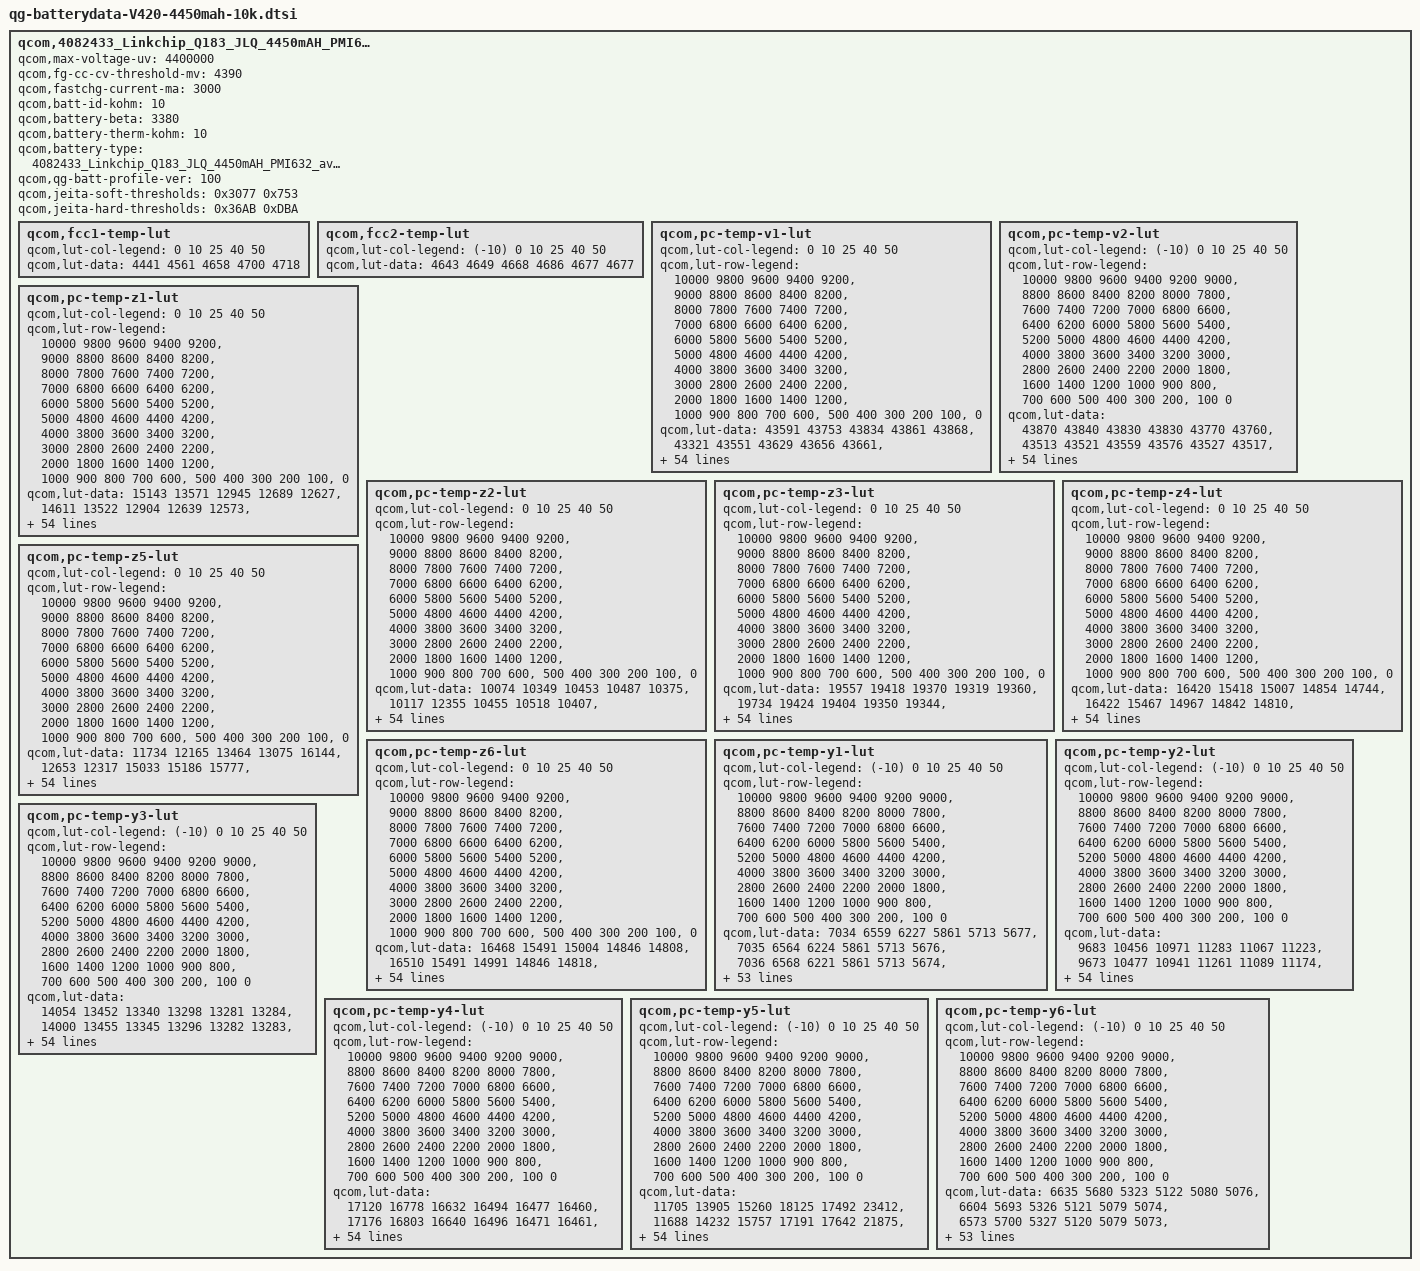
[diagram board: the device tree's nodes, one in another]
qcom,4082433_Linkchip_Q183_JLQ_4450mAH_PMI632 {
    /* 4082433_Linkchip_Q183_JLQ_4450mAH_PMI632_averaged_MasterSlave_Jul1th2019 */
    qcom,max-voltage-uv = <4400000>;
    qcom,fg-cc-cv-threshold-mv = <4390>;
    qcom,fastchg-current-ma = <3000>;
    qcom,batt-id-kohm = <10>;
    qcom,battery-beta = <3380>;
    qcom,battery-therm-kohm = <10>;
    qcom,battery-type = "4082433_Linkchip_Q183_JLQ_4450mAH_PMI632_averaged_MasterSlave_Jul1th2019";
    qcom,qg-batt-profile-ver = <100>;
    /* COOL = 5 DegC, WARM = 45 DegC */
    qcom,jeita-soft-thresholds = <0x3077 0x753>;
    /* COLD = 0 DegC, HOT = 50 DegC */
    qcom,jeita-hard-thresholds = <0x36AB 0xDBA>;
	qcom,fcc1-temp-lut {
		qcom,lut-col-legend = <0 10 25 40 50>;
		qcom,lut-data = <4441 4561 4658 4700 4718>;
	};

	qcom,fcc2-temp-lut {
		qcom,lut-col-legend = <(-10) 0 10 25 40 50>;
		qcom,lut-data = <4643 4649 4668 4686 4677 4677>;
	};

	qcom,pc-temp-v1-lut {
		qcom,lut-col-legend = <0 10 25 40 50>;
		qcom,lut-row-legend = <10000 9800 9600 9400 9200>,
			<9000 8800 8600 8400 8200>,
			<8000 7800 7600 7400 7200>,
			<7000 6800 6600 6400 6200>,
			<6000 5800 5600 5400 5200>,
			<5000 4800 4600 4400 4200>,
			<4000 3800 3600 3400 3200>,
			<3000 2800 2600 2400 2200>,
			<2000 1800 1600 1400 1200>,
			<1000 900 800 700 600>,
			<500 400 300 200 100>,
			<0>;
		qcom,lut-data = <43591 43753 43834 43861 43868>,
			<43321 43551 43629 43656 43661>,
			<43061 43282 43402 43441 43451>,
			<42814 43041 43171 43219 43235>,
			<42578 42801 42931 42986 43006>,
			<42350 42560 42691 42750 42773>,
			<42129 42324 42453 42516 42538>,
			<41914 42096 42218 42282 42301>,
			<41702 41875 41987 42050 42068>,
			<41489 41657 41760 41819 41837>,
			<41289 41441 41535 41591 41609>,
			<41119 41238 41313 41366 41384>,
			<40950 41065 41104 41146 41162>,
			<40722 40896 40920 40935 40950>,
			<40413 40669 40734 40729 40745>,
			<40152 40373 40509 40527 40544>,
			<39978 40131 40262 40327 40348>,
			<39836 39975 40068 40139 40160>,
			<39702 39843 39923 39970 39987>,
			<39581 39706 39776 39802 39816>,
			<39462 39572 39608 39612 39626>,
			<39339 39423 39425 39405 39417>,
			<39217 39253 39203 39201 39213>,
			<39100 39073 38939 38989 39008>,
			<38987 38877 38760 38813 38830>,
			<38879 38677 38661 38694 38704>,
			<38778 38552 38580 38595 38601>,
			<38682 38476 38496 38496 38497>,
			<38593 38417 38418 38401 38396>,
			<38509 38367 38346 38314 38304>,
			<38437 38325 38278 38237 38223>,
			<38378 38287 38218 38168 38150>,
			<38328 38253 38169 38108 38088>,
			<38284 38220 38123 38054 38032>,
			<38247 38191 38080 38001 37973>,
			<38208 38159 38039 37951 37909>,
			<38168 38121 37995 37899 37845>,
			<38125 38077 37950 37848 37786>,
			<38068 38019 37894 37788 37720>,
			<37995 37936 37810 37705 37634>,
			<37905 37830 37700 37599 37527>,
			<37783 37706 37580 37481 37406>,
			<37639 37559 37444 37344 37267>,
			<37482 37404 37290 37196 37117>,
			<37341 37262 37148 37058 36984>,
			<37232 37161 37063 36973 36914>,
			<37194 37132 37038 36949 36888>,
			<37172 37107 37022 36932 36870>,
			<37142 37084 37004 36912 36851>,
			<37094 37040 36952 36846 36771>,
			<36888 36826 36714 36577 36482>,
			<36458 36401 36283 36128 36028>,
			<35888 35837 35714 35548 35451>,
			<35127 35075 34941 34759 34660>,
			<33954 33914 33760 33544 33439>,
			<30000 30000 30000 30000 30000>;
	};

	qcom,pc-temp-v2-lut {
		qcom,lut-col-legend = <(-10) 0 10 25 40 50>;
		qcom,lut-row-legend = <10000 9800 9600 9400 9200 9000>,
			<8800 8600 8400 8200 8000 7800>,
			<7600 7400 7200 7000 6800 6600>,
			<6400 6200 6000 5800 5600 5400>,
			<5200 5000 4800 4600 4400 4200>,
			<4000 3800 3600 3400 3200 3000>,
			<2800 2600 2400 2200 2000 1800>,
			<1600 1400 1200 1000 900 800>,
			<700 600 500 400 300 200>,
			<100 0>;
		qcom,lut-data = <43870 43840 43830 43830 43770 43760>,
			<43513 43521 43559 43576 43527 43517>,
			<43175 43222 43297 43327 43287 43277>,
			<42857 42946 43044 43083 43048 43039>,
			<42557 42690 42800 42843 42813 42804>,
			<42275 42438 42557 42603 42577 42568>,
			<42013 42182 42315 42364 42340 42332>,
			<41762 41938 42077 42128 42104 42097>,
			<41500 41722 41846 41897 41871 41866>,
			<41248 41522 41620 41670 41641 41638>,
			<41075 41316 41395 41443 41414 41411>,
			<40973 41102 41171 41217 41191 41189>,
			<40834 40888 40961 41001 40972 40970>,
			<40455 40689 40786 40807 40763 40759>,
			<39977 40478 40609 40612 40557 40552>,
			<39700 40193 40370 40384 40356 40352>,
			<39511 39830 40076 40138 40160 40159>,
			<39336 39563 39828 39943 39976 39975>,
			<39168 39396 39629 39798 39809 39806>,
			<39007 39247 39440 39642 39632 39628>,
			<38844 39073 39241 39418 39415 39414>,
			<38686 38897 39046 39173 39184 39189>,
			<38545 38737 38874 38968 38980 38986>,
			<38416 38591 38718 38784 38791 38797>,
			<38306 38453 38580 38631 38636 38640>,
			<38216 38316 38459 38508 38512 38515>,
			<38138 38194 38352 38400 38405 38405>,
			<38070 38103 38251 38299 38304 38303>,
			<38010 38031 38158 38207 38212 38210>,
			<37951 37970 38072 38124 38129 38123>,
			<37895 37920 37993 38049 38053 38045>,
			<37841 37874 37921 37979 37982 37973>,
			<37788 37830 37856 37913 37919 37911>,
			<37735 37786 37798 37849 37856 37848>,
			<37679 37741 37753 37788 37780 37766>,
			<37620 37695 37716 37729 37693 37666>,
			<37556 37643 37674 37664 37607 37567>,
			<37491 37581 37626 37592 37519 37466>,
			<37423 37510 37568 37518 37434 37372>,
			<37356 37429 37494 37445 37358 37292>,
			<37287 37337 37403 37365 37281 37213>,
			<37221 37244 37297 37267 37184 37120>,
			<37148 37148 37178 37148 37068 37005>,
			<37070 37058 37049 37016 36935 36873>,
			<36979 36949 36944 36899 36823 36766>,
			<36865 36839 36872 36858 36797 36740>,
			<36800 36785 36839 36844 36783 36730>,
			<36728 36712 36810 36826 36765 36715>,
			<36622 36632 36762 36790 36739 36686>,
			<36468 36537 36665 36694 36629 36554>,
			<36241 36343 36425 36379 36291 36200>,
			<35884 35980 35947 35890 35797 35712>,
			<35365 35417 35318 35260 35168 35067>,
			<34582 34610 34475 34387 34300 34201>,
			<33313 33287 33171 33114 32972 32855>,
			<31074 30710 30689 30381 29206 29172>;
	};

	qcom,pc-temp-z1-lut {
		qcom,lut-col-legend = <0 10 25 40 50>;
		qcom,lut-row-legend = <10000 9800 9600 9400 9200>,
			<9000 8800 8600 8400 8200>,
			<8000 7800 7600 7400 7200>,
			<7000 6800 6600 6400 6200>,
			<6000 5800 5600 5400 5200>,
			<5000 4800 4600 4400 4200>,
			<4000 3800 3600 3400 3200>,
			<3000 2800 2600 2400 2200>,
			<2000 1800 1600 1400 1200>,
			<1000 900 800 700 600>,
			<500 400 300 200 100>,
			<0>;
		qcom,lut-data = <15143 13571 12945 12689 12627>,
			<14611 13522 12904 12639 12573>,
			<14256 13504 12872 12616 12556>,
			<14178 13482 12853 12604 12540>,
			<14154 13464 12842 12593 12533>,
			<14141 13447 12831 12584 12528>,
			<14131 13433 12819 12579 12525>,
			<14123 13422 12811 12575 12523>,
			<14114 13413 12805 12572 12521>,
			<14104 13405 12800 12569 12519>,
			<14093 13399 12797 12569 12518>,
			<14079 13392 12795 12569 12520>,
			<14062 13382 12793 12569 12524>,
			<14041 13368 12789 12569 12524>,
			<14012 13350 12784 12569 12523>,
			<13989 13326 12780 12569 12523>,
			<13974 13315 12775 12570 12526>,
			<13962 13320 12775 12571 12529>,
			<13957 13329 12782 12573 12529>,
			<13955 13335 12789 12575 12529>,
			<13952 13338 12792 12576 12529>,
			<13949 13344 12795 12577 12530>,
			<13947 13359 12798 12578 12532>,
			<13946 13371 12800 12579 12533>,
			<13946 13369 12803 12581 12535>,
			<13946 13366 12807 12585 12538>,
			<13945 13365 12810 12588 12541>,
			<13944 13374 12814 12592 12544>,
			<13944 13382 12818 12595 12549>,
			<13947 13384 12822 12599 12552>,
			<13952 13385 12827 12603 12555>,
			<13957 13389 12831 12608 12557>,
			<13963 13397 12835 12611 12560>,
			<13970 13406 12839 12615 12564>,
			<13977 13411 12844 12619 12568>,
			<13985 13415 12851 12622 12572>,
			<13993 13424 12857 12626 12576>,
			<14003 13440 12864 12630 12578>,
			<14014 13452 12871 12634 12580>,
			<14027 13460 12876 12640 12585>,
			<14041 13467 12881 12645 12591>,
			<14053 13478 12887 12650 12595>,
			<14066 13491 12894 12655 12598>,
			<14082 13505 12902 12659 12603>,
			<14099 13519 12911 12664 12608>,
			<14109 13521 12920 12670 12608>,
			<14106 13521 12921 12671 12611>,
			<14105 13525 12924 12673 12615>,
			<14110 13535 12929 12677 12620>,
			<14122 13548 12937 12685 12625>,
			<14140 13560 12948 12694 12634>,
			<14153 13570 12962 12706 12646>,
			<14170 13593 12980 12720 12660>,
			<14194 13630 13008 12741 12679>,
			<14194 13630 13008 12741 12679>,
			<14194 13630 13008 12741 12679>;
	};

	qcom,pc-temp-z2-lut {
		qcom,lut-col-legend = <0 10 25 40 50>;
		qcom,lut-row-legend = <10000 9800 9600 9400 9200>,
			<9000 8800 8600 8400 8200>,
			<8000 7800 7600 7400 7200>,
			<7000 6800 6600 6400 6200>,
			<6000 5800 5600 5400 5200>,
			<5000 4800 4600 4400 4200>,
			<4000 3800 3600 3400 3200>,
			<3000 2800 2600 2400 2200>,
			<2000 1800 1600 1400 1200>,
			<1000 900 800 700 600>,
			<500 400 300 200 100>,
			<0>;
		qcom,lut-data = <10074 10349 10453 10487 10375>,
			<10117 12355 10455 10518 10407>,
			<10156 10282 10500 10394 10324>,
			<10189 10265 10491 10548 10323>,
			<10219 10248 10476 10530 10404>,
			<10242 10229 10462 10504 10496>,
			<10262 10213 10453 10474 10489>,
			<10275 10202 10442 10442 10452>,
			<10274 10194 10423 10427 10425>,
			<10258 10184 10402 10418 10404>,
			<10240 10169 10393 10411 10394>,
			<10229 10161 10388 10405 10400>,
			<10217 10219 10387 10398 10407>,
			<10190 10309 10396 10364 10375>,
			<10133 10303 10408 10308 10279>,
			<10097 10207 10417 10304 10249>,
			<10092 10157 10424 10354 10272>,
			<10089 10177 10434 10383 10295>,
			<10087 10208 10445 10373 10304>,
			<10085 10226 10459 10361 10313>,
			<10083 10239 10483 10420 10383>,
			<10076 10254 10506 10575 10583>,
			<10068 10275 10506 10609 10651>,
			<10063 10290 10496 10518 10531>,
			<10060 10290 10482 10447 10428>,
			<10058 10289 10450 10433 10427>,
			<10062 10290 10426 10426 10429>,
			<10069 10296 10447 10458 10439>,
			<10078 10302 10492 10565 10471>,
			<10088 10297 10508 10602 10484>,
			<10095 10290 10512 10547 10438>,
			<10098 10287 10516 10491 10371>,
			<10099 10286 10520 10472 10311>,
			<10103 10285 10524 10461 10256>,
			<10108 10287 10530 10467 10252>,
			<10113 10290 10539 10505 10292>,
			<10119 10294 10549 10541 10343>,
			<10125 10298 10557 10567 10405>,
			<10132 10304 10567 10592 10464>,
			<10142 10318 10585 10619 10492>,
			<10150 10333 10604 10645 10510>,
			<10154 10339 10608 10659 10533>,
			<10160 10344 10608 10667 10562>,
			<10234 10358 10614 10653 10602>,
			<10340 10455 10643 10607 10627>,
			<10379 10709 10701 10583 10531>,
			<10339 10788 10645 10590 10536>,
			<9807 10857 10708 10626 10527>,
			<9999 10856 10909 10654 10616>,
			<14944 10917 10929 10699 10631>,
			<9977 10860 10873 10628 10444>,
			<9711 10729 10895 10524 10341>,
			<10011 10527 10789 10448 10281>,
			<9804 10297 10719 10395 10211>,
			<9804 10297 10719 10395 10211>,
			<9804 10297 10719 10395 10211>;
	};

	qcom,pc-temp-z3-lut {
		qcom,lut-col-legend = <0 10 25 40 50>;
		qcom,lut-row-legend = <10000 9800 9600 9400 9200>,
			<9000 8800 8600 8400 8200>,
			<8000 7800 7600 7400 7200>,
			<7000 6800 6600 6400 6200>,
			<6000 5800 5600 5400 5200>,
			<5000 4800 4600 4400 4200>,
			<4000 3800 3600 3400 3200>,
			<3000 2800 2600 2400 2200>,
			<2000 1800 1600 1400 1200>,
			<1000 900 800 700 600>,
			<500 400 300 200 100>,
			<0>;
		qcom,lut-data = <19557 19418 19370 19319 19360>,
			<19734 19424 19404 19350 19344>,
			<19845 19602 19441 19363 19353>,
			<19857 19633 19457 19392 19370>,
			<19845 19651 19465 19398 19381>,
			<19827 19666 19467 19400 19387>,
			<19787 19674 19465 19400 19392>,
			<19744 19670 19464 19399 19395>,
			<19738 19661 19463 19399 19396>,
			<19742 19655 19462 19400 19397>,
			<19745 19652 19461 19400 19397>,
			<19736 19648 19461 19398 19396>,
			<19723 19641 19460 19393 19392>,
			<19734 19633 19442 19388 19386>,
			<19800 19632 19424 19381 19376>,
			<19840 19632 19429 19380 19371>,
			<19824 19631 19444 19381 19369>,
			<19796 19609 19447 19381 19367>,
			<19779 19581 19433 19377 19363>,
			<19766 19575 19425 19372 19358>,
			<19761 19572 19429 19375 19360>,
			<19767 19572 19437 19384 19366>,
			<19780 19589 19442 19386 19368>,
			<19793 19608 19446 19376 19359>,
			<19808 19611 19446 19367 19351>,
			<19819 19613 19436 19363 19354>,
			<19824 19614 19428 19361 19362>,
			<19828 19614 19428 19369 19374>,
			<19828 19614 19430 19395 19395>,
			<19827 19611 19434 19406 19403>,
			<19825 19606 19443 19405 19398>,
			<19820 19602 19447 19404 19391>,
			<19810 19598 19447 19401 19383>,
			<19800 19593 19446 19394 19374>,
			<19787 19586 19445 19388 19367>,
			<19774 19578 19443 19382 19361>,
			<19762 19575 19440 19377 19358>,
			<19749 19574 19437 19374 19356>,
			<19733 19572 19434 19372 19355>,
			<19711 19564 19431 19369 19355>,
			<19691 19556 19429 19367 19356>,
			<19680 19553 19426 19367 19357>,
			<19665 19552 19423 19368 19361>,
			<19627 19541 19421 19368 19365>,
			<19465 19497 19415 19363 19366>,
			<19349 19420 19387 19351 19340>,
			<19346 19345 19376 19347 19334>,
			<19268 19325 19344 19341 19333>,
			<19265 19320 19321 19338 19322>,
			<19257 19315 19321 19333 19326>,
			<19265 19315 19331 19341 19348>,
			<19270 19317 19333 19352 19356>,
			<19364 19323 19332 19355 19354>,
			<19374 19323 19329 19355 19352>,
			<19374 19323 19329 19355 19352>,
			<19374 19323 19329 19355 19352>;
	};

	qcom,pc-temp-z4-lut {
		qcom,lut-col-legend = <0 10 25 40 50>;
		qcom,lut-row-legend = <10000 9800 9600 9400 9200>,
			<9000 8800 8600 8400 8200>,
			<8000 7800 7600 7400 7200>,
			<7000 6800 6600 6400 6200>,
			<6000 5800 5600 5400 5200>,
			<5000 4800 4600 4400 4200>,
			<4000 3800 3600 3400 3200>,
			<3000 2800 2600 2400 2200>,
			<2000 1800 1600 1400 1200>,
			<1000 900 800 700 600>,
			<500 400 300 200 100>,
			<0>;
		qcom,lut-data = <16420 15418 15007 14854 14744>,
			<16422 15467 14967 14842 14810>,
			<16422 15509 14949 14820 14792>,
			<16377 15368 14972 14851 14830>,
			<16153 15244 14913 14830 14815>,
			<15945 15143 14869 14805 14791>,
			<15830 15058 14838 14788 14774>,
			<15735 14996 14813 14773 14759>,
			<15641 14947 14792 14758 14744>,
			<15549 14910 14773 14743 14730>,
			<15463 14883 14758 14730 14717>,
			<15382 14854 14744 14718 14706>,
			<15306 14805 14734 14708 14697>,
			<15238 14758 14727 14705 14696>,
			<15177 14754 14722 14703 14696>,
			<15125 14769 14717 14699 14695>,
			<15083 14777 14712 14692 14690>,
			<15047 14770 14705 14685 14684>,
			<15017 14758 14696 14680 14679>,
			<14991 14745 14691 14677 14675>,
			<14964 14730 14692 14682 14679>,
			<14934 14725 14696 14701 14699>,
			<14904 14728 14722 14728 14727>,
			<14877 14734 14797 14781 14775>,
			<14852 14766 14827 14813 14807>,
			<14834 14828 14819 14808 14797>,
			<14821 14845 14806 14796 14771>,
			<14811 14834 14792 14774 14744>,
			<14805 14820 14775 14734 14712>,
			<14802 14806 14758 14710 14695>,
			<14799 14790 14741 14700 14690>,
			<14797 14776 14727 14693 14687>,
			<14796 14763 14717 14689 14683>,
			<14793 14751 14709 14685 14679>,
			<14790 14741 14703 14685 14680>,
			<14786 14731 14699 14687 14684>,
			<14783 14724 14696 14688 14687>,
			<14779 14717 14694 14688 14686>,
			<14780 14714 14692 14687 14686>,
			<14785 14714 14694 14690 14688>,
			<14789 14714 14697 14697 14694>,
			<14790 14712 14696 14698 14694>,
			<14791 14708 14690 14690 14686>,
			<14804 14710 14686 14689 14685>,
			<14887 14717 14680 14688 14684>,
			<14948 14740 14664 14664 14664>,
			<14951 14820 14669 14660 14663>,
			<15028 14837 14693 14650 14649>,
			<15022 14838 14710 14637 14639>,
			<15012 14837 14706 14640 14630>,
			<15005 14842 14712 14660 14644>,
			<15026 14851 14718 14661 14652>,
			<14950 14856 14726 14663 14658>,
			<14969 14873 14736 14669 14665>,
			<14969 14873 14736 14669 14665>,
			<14969 14873 14736 14669 14665>;
	};

	qcom,pc-temp-z5-lut {
		qcom,lut-col-legend = <0 10 25 40 50>;
		qcom,lut-row-legend = <10000 9800 9600 9400 9200>,
			<9000 8800 8600 8400 8200>,
			<8000 7800 7600 7400 7200>,
			<7000 6800 6600 6400 6200>,
			<6000 5800 5600 5400 5200>,
			<5000 4800 4600 4400 4200>,
			<4000 3800 3600 3400 3200>,
			<3000 2800 2600 2400 2200>,
			<2000 1800 1600 1400 1200>,
			<1000 900 800 700 600>,
			<500 400 300 200 100>,
			<0>;
		qcom,lut-data = <11734 12165 13464 13075 16144>,
			<12653 12317 15033 15186 15777>,
			<13311 14582 17007 16598 17196>,
			<13602 15161 16972 18119 17969>,
			<13781 15829 17699 18656 19012>,
			<13846 16730 18260 18903 19863>,
			<13770 17480 18621 19014 20718>,
			<13662 17879 18971 19090 21528>,
			<13707 18173 19348 19314 22339>,
			<13992 18594 19763 19858 23143>,
			<14164 19202 20415 20438 23979>,
			<14148 19847 21414 21123 25118>,
			<14126 20380 21790 21589 26038>,
			<14452 20972 20555 21515 25448>,
			<15998 22293 19257 21326 23476>,
			<16939 24995 21065 21568 22913>,
			<16687 26278 25489 23335 23950>,
			<16317 24248 26527 24710 25049>,
			<16260 21786 25297 25073 25503>,
			<16311 21953 24475 25433 25915>,
			<16407 23778 28400 28094 27413>,
			<17058 27098 33952 33686 30719>,
			<18368 39311 34603 34438 31504>,
			<19959 50005 34546 27038 25004>,
			<22220 50497 34125 20616 19015>,
			<24718 50519 28523 18398 18139>,
			<27369 50179 23289 17113 17701>,
			<30099 46892 22906 18001 18837>,
			<32616 43130 22771 21800 24177>,
			<35231 40728 23196 25071 27719>,
			<36471 38722 26073 27494 29105>,
			<35745 37373 29098 29511 29791>,
			<34183 36469 31222 31268 29392>,
			<32448 35529 33242 32627 28545>,
			<30182 34000 35698 32952 28533>,
			<28104 32676 38352 33053 29465>,
			<26627 32817 39094 33071 30032>,
			<25315 33900 38757 32696 30111>,
			<23753 34358 38176 31952 30147>,
			<21816 32866 37146 30096 29193>,
			<20670 31249 35610 27320 26909>,
			<20494 31181 34044 26706 26639>,
			<20300 31262 32445 26763 28725>,
			<18558 28844 31990 26278 29618>,
			<14424 22735 31178 24635 29667>,
			<12339 16770 25511 23741 22136>,
			<12217 13101 22036 22412 20101>,
			<11320 12421 16149 22174 21543>,
			<11314 12299 14029 23272 20828>,
			<11328 12259 14212 21454 25655>,
			<11408 12363 14760 19325 25194>,
			<11427 12288 14536 19720 23380>,
			<12305 12271 14072 19265 20729>,
			<12150 12064 13638 17960 17850>,
			<12150 12064 13638 17960 17850>,
			<12150 12064 13638 17960 17850>;
	};

	qcom,pc-temp-z6-lut {
		qcom,lut-col-legend = <0 10 25 40 50>;
		qcom,lut-row-legend = <10000 9800 9600 9400 9200>,
			<9000 8800 8600 8400 8200>,
			<8000 7800 7600 7400 7200>,
			<7000 6800 6600 6400 6200>,
			<6000 5800 5600 5400 5200>,
			<5000 4800 4600 4400 4200>,
			<4000 3800 3600 3400 3200>,
			<3000 2800 2600 2400 2200>,
			<2000 1800 1600 1400 1200>,
			<1000 900 800 700 600>,
			<500 400 300 200 100>,
			<0>;
		qcom,lut-data = <16468 15491 15004 14846 14808>,
			<16510 15491 14991 14846 14818>,
			<16520 15565 14997 14841 14812>,
			<16492 15507 15009 14866 14835>,
			<16351 15452 14985 14858 14832>,
			<16213 15403 14964 14848 14827>,
			<16122 15358 14947 14840 14822>,
			<16046 15319 14933 14832 14816>,
			<15984 15285 14921 14826 14811>,
			<15934 15259 14911 14820 14805>,
			<15886 15240 14903 14814 14799>,
			<15828 15220 14897 14807 14794>,
			<15774 15189 14890 14801 14790>,
			<15745 15159 14875 14796 14784>,
			<15728 15149 14863 14792 14779>,
			<15709 15146 14864 14789 14775>,
			<15674 15141 14867 14786 14772>,
			<15636 15127 14867 14784 14769>,
			<15609 15112 14857 14779 14764>,
			<15590 15104 14851 14775 14760>,
			<15575 15098 14853 14779 14762>,
			<15564 15097 14860 14792 14775>,
			<15555 15107 14876 14805 14789>,
			<15550 15124 14911 14823 14805>,
			<15546 15146 14924 14833 14815>,
			<15543 15171 14917 14830 14812>,
			<15539 15177 14908 14824 14806>,
			<15536 15176 14902 14820 14803>,
			<15534 15174 14897 14817 14801>,
			<15533 15168 14894 14814 14798>,
			<15532 15158 14891 14810 14794>,
			<15531 15152 14889 14806 14789>,
			<15530 15148 14885 14803 14784>,
			<15528 15144 14882 14799 14777>,
			<15523 15137 14880 14796 14775>,
			<15519 15130 14879 14794 14774>,
			<15516 15130 14878 14792 14773>,
			<15514 15133 14876 14790 14771>,
			<15513 15134 14875 14789 14771>,
			<15514 15134 14876 14790 14772>,
			<15514 15135 14877 14793 14776>,
			<15519 15137 14877 14793 14777>,
			<15523 15143 14875 14792 14777>,
			<15522 15143 14875 14791 14778>,
			<15499 15138 14873 14790 14779>,
			<15478 15114 14854 14774 14758>,
			<15477 15110 14851 14770 14754>,
			<15474 15111 14846 14764 14748>,
			<15474 15114 14843 14757 14738>,
			<15478 15117 14844 14757 14738>,
			<15487 15125 14855 14771 14757>,
			<15507 15136 14863 14780 14768>,
			<15532 15152 14870 14786 14772>,
			<15566 15178 14882 14794 14778>,
			<15566 15178 14882 14794 14778>,
			<15566 15178 14882 14794 14778>;
	};

	qcom,pc-temp-y1-lut {
		qcom,lut-col-legend = <(-10) 0 10 25 40 50>;
		qcom,lut-row-legend = <10000 9800 9600 9400 9200 9000>,
			<8800 8600 8400 8200 8000 7800>,
			<7600 7400 7200 7000 6800 6600>,
			<6400 6200 6000 5800 5600 5400>,
			<5200 5000 4800 4600 4400 4200>,
			<4000 3800 3600 3400 3200 3000>,
			<2800 2600 2400 2200 2000 1800>,
			<1600 1400 1200 1000 900 800>,
			<700 600 500 400 300 200>,
			<100 0>;
		qcom,lut-data = <7034 6559 6227 5861 5713 5677>,
			<7035 6564 6224 5861 5713 5676>,
			<7036 6568 6221 5861 5713 5674>,
			<7037 6571 6218 5861 5712 5673>,
			<7038 6572 6216 5861 5712 5672>,
			<7040 6572 6214 5861 5711 5671>,
			<7041 6571 6213 5859 5710 5670>,
			<7043 6569 6213 5858 5709 5670>,
			<7057 6572 6213 5857 5708 5669>,
			<7085 6577 6214 5856 5707 5668>,
			<7089 6578 6214 5855 5706 5668>,
			<7065 6577 6213 5854 5705 5668>,
			<7049 6576 6212 5853 5705 5668>,
			<7052 6578 6211 5851 5706 5668>,
			<7057 6580 6210 5849 5707 5669>,
			<7059 6590 6211 5853 5707 5669>,
			<7060 6613 6217 5864 5707 5669>,
			<7061 6621 6221 5866 5708 5670>,
			<7060 6610 6225 5860 5708 5671>,
			<7060 6599 6226 5857 5709 5672>,
			<7060 6594 6225 5858 5709 5673>,
			<7060 6591 6222 5860 5709 5673>,
			<7060 6591 6222 5861 5710 5674>,
			<7060 6593 6222 5862 5713 5675>,
			<7059 6595 6222 5863 5715 5676>,
			<7059 6597 6224 5865 5717 5678>,
			<7058 6598 6226 5866 5718 5680>,
			<7057 6597 6226 5868 5719 5682>,
			<7057 6595 6225 5871 5720 5683>,
			<7057 6594 6226 5873 5722 5685>,
			<7056 6593 6229 5876 5724 5688>,
			<7055 6593 6232 5878 5727 5690>,
			<7054 6593 6231 5880 5730 5693>,
			<7052 6593 6230 5883 5734 5696>,
			<7051 6593 6231 5886 5736 5698>,
			<7051 6594 6236 5888 5738 5700>,
			<7051 6595 6239 5891 5740 5701>,
			<7050 6597 6240 5893 5742 5703>,
			<7049 6599 6241 5896 5744 5705>,
			<7048 6600 6244 5897 5746 5707>,
			<7048 6601 6246 5899 5748 5710>,
			<7048 6603 6248 5902 5750 5712>,
			<7048 6602 6253 5906 5753 5713>,
			<7065 6612 6256 5911 5757 5717>,
			<7115 6616 6265 5916 5761 5721>,
			<7071 6617 6265 5924 5766 5726>,
			<7074 6622 6272 5926 5767 5726>,
			<7076 6627 6270 5927 5768 5726>,
			<7078 6623 6274 5928 5767 5725>,
			<7080 6629 6276 5929 5769 5727>,
			<7085 6634 6282 5937 5773 5731>,
			<7092 6640 6288 5946 5781 5738>,
			<7120 6651 6303 5962 5792 5750>,
			<7167 6671 6322 5983 5806 5762>,
			<7167 6671 6322 5983 5806 5762>,
			<7167 6671 6322 5983 5806 5762>;
	};

	qcom,pc-temp-y2-lut {
		qcom,lut-col-legend = <(-10) 0 10 25 40 50>;
		qcom,lut-row-legend = <10000 9800 9600 9400 9200 9000>,
			<8800 8600 8400 8200 8000 7800>,
			<7600 7400 7200 7000 6800 6600>,
			<6400 6200 6000 5800 5600 5400>,
			<5200 5000 4800 4600 4400 4200>,
			<4000 3800 3600 3400 3200 3000>,
			<2800 2600 2400 2200 2000 1800>,
			<1600 1400 1200 1000 900 800>,
			<700 600 500 400 300 200>,
			<100 0>;
		qcom,lut-data = <9683 10456 10971 11283 11067 11223>,
			<9673 10477 10941 11261 11089 11174>,
			<9669 10497 10911 11237 11098 11127>,
			<9669 10516 10884 11211 11097 11084>,
			<9673 10533 10861 11183 11089 11046>,
			<9678 10547 10843 11154 11077 11013>,
			<9691 10561 10828 11120 11044 10985>,
			<9701 10570 10817 11089 11009 10962>,
			<9698 10557 10809 11067 10991 10943>,
			<9693 10529 10803 11049 10977 10927>,
			<9693 10546 10802 11042 10962 10917>,
			<9704 10701 10808 11039 10945 10912>,
			<9711 10800 10819 11035 10938 10905>,
			<9704 10787 10867 11024 11007 10888>,
			<9690 10770 10924 11013 11086 10872>,
			<9682 10777 10936 11030 11080 10883>,
			<9675 10808 10940 11083 11050 10923>,
			<9673 10838 10951 11143 11052 10967>,
			<9672 10867 10986 11225 11160 11022>,
			<9672 10890 11023 11270 11263 11063>,
			<9671 10905 11046 11262 11306 11076>,
			<9669 10915 11064 11252 11333 11087>,
			<9668 10920 11084 11257 11321 11112>,
			<9667 10922 11104 11283 11265 11160>,
			<9667 10925 11123 11308 11241 11207>,
			<9666 10948 11140 11334 11253 11254>,
			<9666 10974 11152 11355 11275 11288>,
			<9665 10979 11157 11367 11311 11297>,
			<9664 10981 11160 11375 11360 11302>,
			<9663 10980 11162 11388 11386 11322>,
			<9662 10955 11163 11405 11399 11385>,
			<9662 10904 11166 11413 11412 11419>,
			<9661 10514 11182 11414 11428 11418>,
			<9660 9875 11202 11414 11439 11414>,
			<9659 9725 11190 11413 11434 11400>,
			<9659 9705 11136 11409 11412 11361>,
			<9658 9692 11088 11395 11386 11324>,
			<9658 9682 11054 11338 11353 11282>,
			<9657 9674 11019 11302 11319 11259>,
			<9657 9669 10974 11316 11288 11272>,
			<9657 9666 10922 11328 11272 11285>,
			<9657 9663 10862 11311 11302 11247>,
			<9656 9661 10777 11300 11256 11192>,
			<9656 9661 10750 11276 11292 11264>,
			<9656 9659 10638 11225 11259 11170>,
			<9656 9658 10562 11162 11218 11057>,
			<9655 9657 10527 11153 11190 10968>,
			<9655 9657 10488 11148 11154 11050>,
			<9655 9656 10469 11132 11183 11121>,
			<9655 9656 10451 11123 11169 11065>,
			<9655 9655 10407 11079 11112 10902>,
			<9654 9655 9842 11011 10984 10897>,
			<9653 9654 9688 10917 10983 10795>,
			<9651 9653 9667 10819 10825 10701>,
			<9651 9653 9667 10819 10825 10701>,
			<9651 9653 9667 10819 10825 10701>;
	};

	qcom,pc-temp-y3-lut {
		qcom,lut-col-legend = <(-10) 0 10 25 40 50>;
		qcom,lut-row-legend = <10000 9800 9600 9400 9200 9000>,
			<8800 8600 8400 8200 8000 7800>,
			<7600 7400 7200 7000 6800 6600>,
			<6400 6200 6000 5800 5600 5400>,
			<5200 5000 4800 4600 4400 4200>,
			<4000 3800 3600 3400 3200 3000>,
			<2800 2600 2400 2200 2000 1800>,
			<1600 1400 1200 1000 900 800>,
			<700 600 500 400 300 200>,
			<100 0>;
		qcom,lut-data = <14054 13452 13340 13298 13281 13284>,
			<14000 13455 13345 13296 13282 13283>,
			<13948 13459 13350 13295 13283 13282>,
			<13898 13464 13355 13293 13284 13280>,
			<13851 13467 13360 13292 13285 13279>,
			<13807 13468 13362 13291 13285 13279>,
			<13766 13468 13364 13291 13285 13279>,
			<13727 13468 13365 13290 13285 13279>,
			<13681 13475 13366 13294 13286 13281>,
			<13636 13489 13367 13301 13286 13284>,
			<13614 13491 13367 13303 13287 13285>,
			<13604 13479 13367 13303 13287 13285>,
			<13594 13463 13366 13303 13287 13285>,
			<13576 13445 13369 13307 13288 13285>,
			<13554 13427 13371 13312 13289 13286>,
			<13533 13417 13369 13311 13290 13285>,
			<13511 13411 13362 13307 13291 13285>,
			<13500 13407 13357 13307 13292 13285>,
			<13497 13404 13353 13309 13295 13288>,
			<13494 13402 13350 13311 13296 13290>,
			<13486 13397 13345 13309 13294 13289>,
			<13477 13391 13340 13306 13291 13286>,
			<13474 13385 13335 13301 13288 13283>,
			<13474 13380 13329 13294 13284 13280>,
			<13474 13374 13326 13291 13282 13279>,
			<13478 13361 13326 13291 13282 13278>,
			<13486 13348 13326 13291 13281 13278>,
			<13496 13342 13326 13291 13281 13278>,
			<13512 13337 13326 13291 13281 13278>,
			<13531 13336 13325 13292 13281 13278>,
			<13553 13337 13325 13293 13282 13277>,
			<13580 13338 13325 13294 13282 13277>,
			<13615 13342 13320 13295 13282 13278>,
			<13659 13352 13313 13295 13282 13279>,
			<13703 13363 13313 13295 13282 13279>,
			<13747 13376 13319 13295 13281 13278>,
			<13796 13391 13324 13294 13281 13277>,
			<13853 13408 13328 13291 13280 13278>,
			<13915 13427 13331 13288 13280 13278>,
			<13980 13451 13333 13290 13282 13278>,
			<14048 13483 13334 13291 13283 13280>,
			<14127 13534 13335 13290 13282 13280>,
			<14192 13596 13336 13290 13283 13281>,
			<14150 13604 13328 13291 13281 13279>,
			<14235 13675 13332 13290 13278 13276>,
			<14362 13805 13350 13293 13286 13282>,
			<14433 13881 13361 13299 13287 13287>,
			<14508 13944 13376 13304 13290 13290>,
			<14581 14007 13387 13309 13296 13292>,
			<14668 14094 13401 13312 13294 13288>,
			<14779 14163 13408 13307 13289 13285>,
			<14939 14248 13428 13311 13289 13287>,
			<15344 14404 13490 13320 13296 13290>,
			<16227 14714 13600 13329 13302 13298>,
			<16227 14714 13600 13329 13302 13298>,
			<16227 14714 13600 13329 13302 13298>;
	};

	qcom,pc-temp-y4-lut {
		qcom,lut-col-legend = <(-10) 0 10 25 40 50>;
		qcom,lut-row-legend = <10000 9800 9600 9400 9200 9000>,
			<8800 8600 8400 8200 8000 7800>,
			<7600 7400 7200 7000 6800 6600>,
			<6400 6200 6000 5800 5600 5400>,
			<5200 5000 4800 4600 4400 4200>,
			<4000 3800 3600 3400 3200 3000>,
			<2800 2600 2400 2200 2000 1800>,
			<1600 1400 1200 1000 900 800>,
			<700 600 500 400 300 200>,
			<100 0>;
		qcom,lut-data = <17120 16778 16632 16494 16477 16460>,
			<17176 16803 16640 16496 16471 16461>,
			<17257 16848 16650 16499 16467 16461>,
			<17340 16899 16659 16502 16466 16462>,
			<17401 16939 16665 16505 16465 16463>,
			<17418 16953 16667 16509 16465 16464>,
			<17407 16955 16665 16514 16467 16466>,
			<17397 16956 16663 16518 16469 16467>,
			<17411 16961 16666 16515 16471 16467>,
			<17456 16974 16676 16510 16474 16466>,
			<17519 16998 16685 16510 16477 16467>,
			<17630 17057 16695 16519 16482 16470>,
			<17693 17117 16712 16529 16487 16475>,
			<17459 17169 16776 16539 16492 16478>,
			<17127 17207 16843 16551 16497 16483>,
			<17071 17132 16835 16563 16503 16489>,
			<17062 16878 16790 16575 16511 16498>,
			<17050 16779 16752 16596 16524 16509>,
			<17028 16784 16722 16640 16549 16525>,
			<17001 16789 16691 16666 16565 16535>,
			<16969 16770 16646 16629 16557 16532>,
			<16935 16724 16601 16566 16537 16523>,
			<16909 16692 16577 16527 16513 16508>,
			<16887 16667 16563 16497 16480 16478>,
			<16877 16648 16554 16486 16468 16466>,
			<16876 16632 16549 16484 16468 16466>,
			<16876 16622 16545 16484 16468 16466>,
			<16876 16622 16542 16485 16470 16468>,
			<16877 16627 16540 16488 16475 16472>,
			<16878 16632 16536 16491 16481 16477>,
			<16880 16638 16529 16495 16488 16484>,
			<16881 16647 16524 16499 16495 16492>,
			<16879 16673 16530 16502 16505 16503>,
			<16876 16711 16538 16504 16514 16512>,
			<16876 16730 16542 16503 16509 16508>,
			<16880 16739 16545 16497 16493 16494>,
			<16886 16747 16549 16492 16480 16482>,
			<16897 16755 16558 16485 16468 16469>,
			<16912 16761 16567 16482 16462 16462>,
			<16927 16766 16573 16482 16466 16466>,
			<16944 16769 16578 16483 16471 16471>,
			<16961 16773 16583 16489 16473 16473>,
			<16974 16779 16580 16490 16473 16474>,
			<16923 16761 16565 16475 16460 16458>,
			<16920 16776 16575 16471 16451 16446>,
			<16950 16817 16597 16489 16464 16463>,
			<16972 16852 16628 16501 16479 16488>,
			<16994 16904 16687 16524 16510 16523>,
			<17012 16970 16743 16560 16557 16570>,
			<17032 17027 16823 16598 16554 16545>,
			<17048 17054 16824 16552 16487 16483>,
			<17042 17045 16823 16550 16488 16485>,
			<17162 17033 16871 16591 16504 16487>,
			<17590 17103 16988 16651 16550 16531>,
			<17590 17103 16988 16651 16550 16531>,
			<17590 17103 16988 16651 16550 16531>;
	};

	qcom,pc-temp-y5-lut {
		qcom,lut-col-legend = <(-10) 0 10 25 40 50>;
		qcom,lut-row-legend = <10000 9800 9600 9400 9200 9000>,
			<8800 8600 8400 8200 8000 7800>,
			<7600 7400 7200 7000 6800 6600>,
			<6400 6200 6000 5800 5600 5400>,
			<5200 5000 4800 4600 4400 4200>,
			<4000 3800 3600 3400 3200 3000>,
			<2800 2600 2400 2200 2000 1800>,
			<1600 1400 1200 1000 900 800>,
			<700 600 500 400 300 200>,
			<100 0>;
		qcom,lut-data = <11705 13905 15260 18125 17492 23412>,
			<11688 14232 15757 17191 17642 21875>,
			<11735 14745 16399 16281 17730 19993>,
			<11834 15284 17024 15445 17772 18132>,
			<11974 15688 17473 14735 17786 16657>,
			<12149 15804 17593 14195 17756 15906>,
			<12440 15751 17527 13713 17204 15511>,
			<12656 15700 17397 13451 16561 15325>,
			<12454 16466 17062 14130 16290 15874>,
			<11996 18104 16477 15409 16092 16940>,
			<12183 18191 15985 15540 15793 17073>,
			<14260 16136 15506 14949 15352 16545>,
			<15621 14834 15301 14644 15032 16012>,
			<15140 16631 15332 14897 14845 15663>,
			<14249 19050 15415 15177 14735 15320>,
			<13476 19088 16312 14979 14724 14813>,
			<12692 18338 18710 14453 14721 14224>,
			<12447 18092 19907 14379 14735 14095>,
			<12741 18884 20340 15141 14919 14414>,
			<13018 19666 20523 16332 15269 14936>,
			<12935 19817 20512 18866 17054 15985>,
			<12694 19896 20475 21515 19421 17286>,
			<12459 19874 20042 21011 19651 17927>,
			<12208 19605 18415 18355 19261 18344>,
			<12001 19121 17663 17283 18888 18457>,
			<11839 17075 18080 17243 18600 18221>,
			<11729 14590 18642 17228 18324 17853>,
			<11712 13747 18940 17348 18006 17476>,
			<11708 13286 19169 17695 17711 17053>,
			<11703 13144 19441 18294 17694 16678>,
			<11692 13124 19805 19531 17965 16300>,
			<11685 13100 19983 20593 18307 16144>,
			<11782 12808 18090 21291 18667 16758>,
			<11973 12333 15505 21842 19075 17751>,
			<12012 12302 15561 22305 19566 18429>,
			<11986 12604 16830 22684 20109 19006>,
			<11946 12844 17881 22366 20251 19530>,
			<11855 12962 18716 19381 20166 20089>,
			<11765 13031 19183 17392 20102 20385>,
			<11768 12893 18934 17727 20370 20177>,
			<11821 12587 18366 17971 20629 19889>,
			<12058 12535 17725 17062 19623 19759>,
			<12208 12477 17200 16973 19364 20122>,
			<12306 12655 15249 18505 19649 20898>,
			<12526 12502 14978 17302 16840 17088>,
			<12590 12856 16275 16272 18387 17217>,
			<12701 13197 16524 17739 17439 17814>,
			<13048 13040 16981 18388 17143 17127>,
			<13162 13162 17507 18498 17708 16918>,
			<13265 14256 18012 18381 16912 15746>,
			<13326 14586 18011 18233 18614 16996>,
			<13123 14210 14995 19465 17681 17460>,
			<12257 13158 13468 20473 20888 17735>,
			<11039 12040 12746 19809 22053 21625>,
			<11039 12040 12746 19809 22053 21625>,
			<11039 12040 12746 19809 22053 21625>;
	};

	qcom,pc-temp-y6-lut {
		qcom,lut-col-legend = <(-10) 0 10 25 40 50>;
		qcom,lut-row-legend = <10000 9800 9600 9400 9200 9000>,
			<8800 8600 8400 8200 8000 7800>,
			<7600 7400 7200 7000 6800 6600>,
			<6400 6200 6000 5800 5600 5400>,
			<5200 5000 4800 4600 4400 4200>,
			<4000 3800 3600 3400 3200 3000>,
			<2800 2600 2400 2200 2000 1800>,
			<1600 1400 1200 1000 900 800>,
			<700 600 500 400 300 200>,
			<100 0>;
		qcom,lut-data = <6635 5680 5323 5122 5080 5076>,
			<6604 5693 5326 5121 5079 5074>,
			<6573 5700 5327 5120 5079 5073>,
			<6541 5704 5327 5120 5080 5072>,
			<6509 5705 5326 5120 5080 5071>,
			<6477 5705 5324 5120 5080 5071>,
			<6443 5694 5320 5120 5081 5072>,
			<6410 5684 5317 5120 5081 5073>,
			<6372 5687 5317 5122 5082 5074>,
			<6335 5696 5317 5124 5083 5075>,
			<6329 5698 5317 5127 5085 5077>,
			<6348 5698 5318 5128 5086 5078>,
			<6359 5697 5319 5131 5088 5079>,
			<6282 5696 5336 5137 5089 5080>,
			<6167 5695 5355 5143 5092 5082>,
			<6135 5670 5351 5146 5094 5084>,
			<6122 5598 5334 5148 5097 5086>,
			<6113 5570 5319 5152 5102 5089>,
			<6107 5573 5309 5166 5111 5096>,
			<6101 5575 5298 5175 5116 5100>,
			<6092 5567 5282 5163 5113 5098>,
			<6084 5549 5265 5143 5105 5093>,
			<6082 5541 5255 5128 5095 5086>,
			<6083 5537 5247 5115 5083 5076>,
			<6084 5534 5245 5110 5078 5072>,
			<6092 5530 5245 5110 5078 5071>,
			<6106 5528 5245 5109 5078 5071>,
			<6121 5529 5246 5110 5078 5072>,
			<6139 5537 5246 5112 5080 5073>,
			<6159 5547 5247 5114 5082 5075>,
			<6182 5561 5249 5116 5084 5076>,
			<6209 5577 5251 5119 5087 5079>,
			<6239 5598 5251 5121 5090 5083>,
			<6273 5622 5252 5122 5093 5086>,
			<6309 5650 5255 5122 5092 5085>,
			<6347 5682 5265 5121 5087 5081>,
			<6389 5718 5276 5120 5083 5077>,
			<6437 5761 5287 5117 5080 5074>,
			<6488 5808 5299 5115 5078 5072>,
			<6543 5857 5311 5116 5081 5074>,
			<6600 5910 5323 5119 5083 5077>,
			<6663 5975 5338 5121 5084 5078>,
			<6719 6041 5357 5123 5084 5079>,
			<6689 6048 5347 5120 5080 5073>,
			<6755 6118 5384 5120 5076 5068>,
			<6857 6239 5435 5130 5086 5078>,
			<6919 6315 5477 5139 5092 5089>,
			<6987 6382 5527 5150 5103 5101>,
			<7050 6451 5563 5165 5120 5117>,
			<7123 6536 5611 5178 5118 5107>,
			<7216 6602 5638 5163 5096 5087>,
			<7342 6674 5669 5171 5098 5090>,
			<7732 6797 5780 5196 5109 5094>,
			<8599 7075 5962 5228 5128 5115>,
			<8599 7075 5962 5228 5128 5115>,
			<8599 7075 5962 5228 5128 5115>;
	};

};
